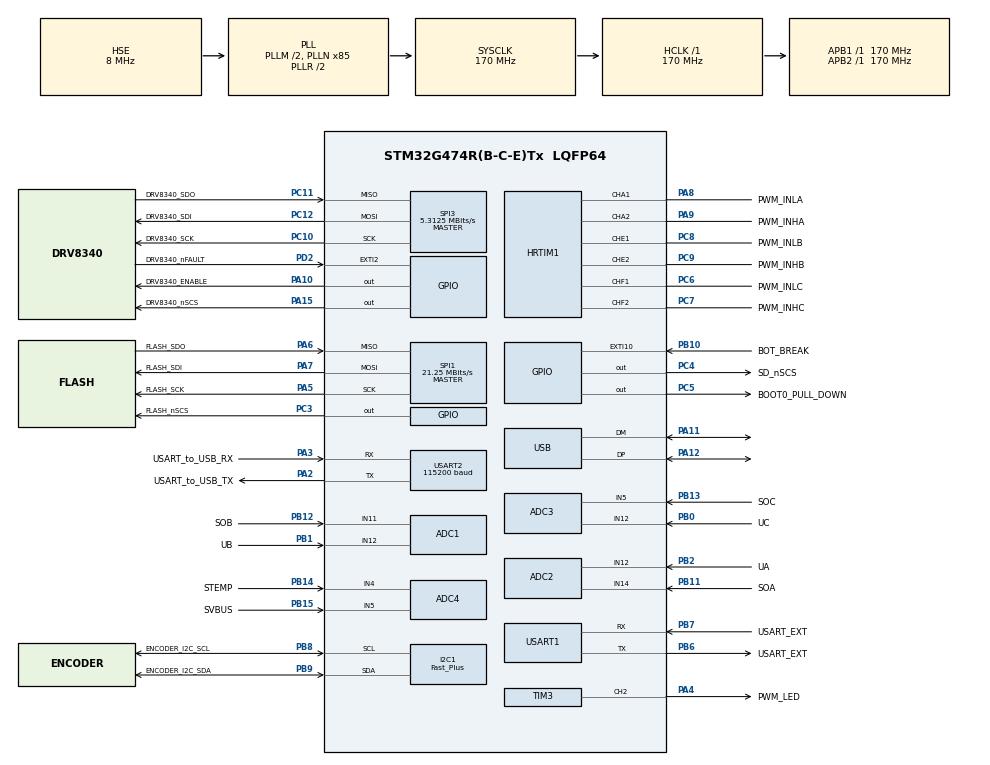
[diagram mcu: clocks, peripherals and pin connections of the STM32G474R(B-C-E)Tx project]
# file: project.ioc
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ADC1.Channel-1\#ChannelRegularConversion=ADC_CHANNEL_11
ADC1.DMAContinuousRequests=ENABLE
ADC1.DiscontinuousConvMode=DISABLE
ADC1.ExternalTrigConv=ADC_EXTERNALTRIG_HRTIM_TRG1
ADC1.ExternalTrigConvEdge=ADC_EXTERNALTRIGCONVEDGE_RISING
ADC1.NbrOfConversion=1
ADC1.NbrOfConversionFlag=1
ADC1.Offset-1\#ChannelRegularConversion=5
ADC1.OffsetNumber-1\#ChannelRegularConversion=ADC_OFFSET_1
ADC1.OffsetSaturation-1\#ChannelRegularConversion=ENABLE
ADC1.Overrun=ADC_OVR_DATA_OVERWRITTEN
ADC1.Rank-1\#ChannelRegularConversion=1
ADC1.SamplingTime-1\#ChannelRegularConversion=ADC_SAMPLETIME_6CYCLES_5
ADC1.master=1
ADC2.Channel-1\#ChannelRegularConversion=ADC_CHANNEL_14
ADC2.DMAContinuousRequests=ENABLE
ADC2.DiscontinuousConvMode=DISABLE
ADC2.ExternalTrigConv=ADC_EXTERNALTRIG_HRTIM_TRG1
ADC2.NbrOfConversion=1
ADC2.NbrOfConversionFlag=1
ADC2.OffsetNumber-1\#ChannelRegularConversion=ADC_OFFSET_NONE
ADC2.Overrun=ADC_OVR_DATA_OVERWRITTEN
ADC2.Rank-1\#ChannelRegularConversion=1
ADC2.SamplingTime-1\#ChannelRegularConversion=ADC_SAMPLETIME_6CYCLES_5
ADC3.Channel-3\#ChannelRegularConversion=ADC_CHANNEL_5
ADC3.DMAContinuousRequests=ENABLE
ADC3.DiscontinuousConvMode=DISABLE
ADC3.ExternalTrigConv=ADC_EXTERNALTRIG_HRTIM_TRG1
ADC3.NbrOfConversion=1
ADC3.NbrOfConversionFlag=1
ADC3.Offset-3\#ChannelRegularConversion=9
ADC3.OffsetNumber-3\#ChannelRegularConversion=ADC_OFFSET_1
ADC3.OffsetSaturation-3\#ChannelRegularConversion=ENABLE
ADC3.OffsetSign-3\#ChannelRegularConversion=ADC_OFFSET_SIGN_POSITIVE
ADC3.Overrun=ADC_OVR_DATA_OVERWRITTEN
ADC3.Rank-3\#ChannelRegularConversion=1
ADC3.SamplingTime-3\#ChannelRegularConversion=ADC_SAMPLETIME_6CYCLES_5
ADC3.master=1
ADC4.Channel-3\#ChannelRegularConversion=ADC_CHANNEL_4
ADC4.Channel-4\#ChannelRegularConversion=ADC_CHANNEL_5
ADC4.DMAContinuousRequests=ENABLE
ADC4.DiscontinuousConvMode=ENABLE
ADC4.ExternalTrigConv=ADC_EXTERNALTRIG_HRTIM_TRG1
ADC4.NbrOfConversion=2
ADC4.NbrOfConversionFlag=1
ADC4.OffsetNumber-3\#ChannelRegularConversion=ADC_OFFSET_NONE
ADC4.OffsetNumber-4\#ChannelRegularConversion=ADC_OFFSET_NONE
ADC4.Overrun=ADC_OVR_DATA_OVERWRITTEN
ADC4.Rank-3\#ChannelRegularConversion=1
ADC4.Rank-4\#ChannelRegularConversion=2
ADC4.SamplingTime-3\#ChannelRegularConversion=ADC_SAMPLETIME_6CYCLES_5
ADC4.SamplingTime-4\#ChannelRegularConversion=ADC_SAMPLETIME_6CYCLES_5
Dma.ADC1.0.Direction=DMA_PERIPH_TO_MEMORY
Dma.ADC1.0.EventEnable=DISABLE
Dma.ADC1.0.Instance=DMA1_Channel1
Dma.ADC1.0.MemDataAlignment=DMA_MDATAALIGN_HALFWORD
Dma.ADC1.0.MemInc=DMA_MINC_ENABLE
Dma.ADC1.0.Mode=DMA_CIRCULAR
Dma.ADC1.0.PeriphDataAlignment=DMA_PDATAALIGN_HALFWORD
Dma.ADC1.0.PeriphInc=DMA_PINC_DISABLE
Dma.ADC1.0.Polarity=HAL_DMAMUX_REQ_GEN_RISING
Dma.ADC1.0.Priority=DMA_PRIORITY_VERY_HIGH
Dma.ADC1.0.RequestNumber=1
Dma.ADC1.0.SignalID=NONE
Dma.ADC1.0.SyncEnable=DISABLE
Dma.ADC1.0.SyncPolarity=HAL_DMAMUX_SYNC_NO_EVENT
Dma.ADC1.0.SyncRequestNumber=1
Dma.ADC1.0.SyncSignalID=NONE
Dma.ADC2.3.Direction=DMA_PERIPH_TO_MEMORY
Dma.ADC2.3.EventEnable=DISABLE
Dma.ADC2.3.Instance=DMA1_Channel2
Dma.ADC2.3.MemDataAlignment=DMA_MDATAALIGN_HALFWORD
Dma.ADC2.3.MemInc=DMA_MINC_ENABLE
Dma.ADC2.3.Mode=DMA_CIRCULAR
Dma.ADC2.3.PeriphDataAlignment=DMA_PDATAALIGN_HALFWORD
Dma.ADC2.3.PeriphInc=DMA_PINC_DISABLE
Dma.ADC2.3.Polarity=HAL_DMAMUX_REQ_GEN_RISING
Dma.ADC2.3.Priority=DMA_PRIORITY_VERY_HIGH
Dma.ADC2.3.RequestNumber=1
Dma.ADC2.3.SignalID=NONE
Dma.ADC2.3.SyncEnable=DISABLE
Dma.ADC2.3.SyncPolarity=HAL_DMAMUX_SYNC_NO_EVENT
Dma.ADC2.3.SyncRequestNumber=1
Dma.ADC2.3.SyncSignalID=NONE
Dma.ADC3.4.Direction=DMA_PERIPH_TO_MEMORY
Dma.ADC3.4.EventEnable=DISABLE
Dma.ADC3.4.Instance=DMA1_Channel3
Dma.ADC3.4.MemDataAlignment=DMA_MDATAALIGN_HALFWORD
Dma.ADC3.4.MemInc=DMA_MINC_ENABLE
Dma.ADC3.4.Mode=DMA_CIRCULAR
Dma.ADC3.4.PeriphDataAlignment=DMA_PDATAALIGN_HALFWORD
Dma.ADC3.4.PeriphInc=DMA_PINC_DISABLE
Dma.ADC3.4.Polarity=HAL_DMAMUX_REQ_GEN_RISING
Dma.ADC3.4.Priority=DMA_PRIORITY_VERY_HIGH
Dma.ADC3.4.RequestNumber=1
Dma.ADC3.4.SignalID=NONE
Dma.ADC3.4.SyncEnable=DISABLE
Dma.ADC3.4.SyncPolarity=HAL_DMAMUX_SYNC_NO_EVENT
Dma.ADC3.4.SyncRequestNumber=1
Dma.ADC3.4.SyncSignalID=NONE
Dma.ADC4.5.Direction=DMA_PERIPH_TO_MEMORY
Dma.ADC4.5.EventEnable=DISABLE
Dma.ADC4.5.Instance=DMA2_Channel2
Dma.ADC4.5.MemDataAlignment=DMA_MDATAALIGN_HALFWORD
Dma.ADC4.5.MemInc=DMA_MINC_ENABLE
Dma.ADC4.5.Mode=DMA_CIRCULAR
Dma.ADC4.5.PeriphDataAlignment=DMA_PDATAALIGN_HALFWORD
Dma.ADC4.5.PeriphInc=DMA_PINC_DISABLE
Dma.ADC4.5.Polarity=HAL_DMAMUX_REQ_GEN_RISING
Dma.ADC4.5.Priority=DMA_PRIORITY_LOW
Dma.ADC4.5.RequestNumber=1
Dma.ADC4.5.SignalID=NONE
Dma.ADC4.5.SyncEnable=DISABLE
Dma.ADC4.5.SyncPolarity=HAL_DMAMUX_SYNC_NO_EVENT
Dma.ADC4.5.SyncRequestNumber=1
Dma.ADC4.5.SyncSignalID=NONE
Dma.I2C1_RX.2.Direction=DMA_PERIPH_TO_MEMORY
Dma.I2C1_RX.2.EventEnable=DISABLE
Dma.I2C1_RX.2.Instance=DMA2_Channel1
Dma.I2C1_RX.2.MemDataAlignment=DMA_MDATAALIGN_BYTE
Dma.I2C1_RX.2.MemInc=DMA_MINC_ENABLE
Dma.I2C1_RX.2.Mode=DMA_NORMAL
Dma.I2C1_RX.2.PeriphDataAlignment=DMA_PDATAALIGN_BYTE
Dma.I2C1_RX.2.PeriphInc=DMA_PINC_DISABLE
Dma.I2C1_RX.2.Polarity=HAL_DMAMUX_REQ_GEN_RISING
Dma.I2C1_RX.2.Priority=DMA_PRIORITY_HIGH
Dma.I2C1_RX.2.RequestNumber=1
Dma.I2C1_RX.2.SignalID=NONE
Dma.I2C1_RX.2.SyncEnable=DISABLE
Dma.I2C1_RX.2.SyncPolarity=HAL_DMAMUX_SYNC_NO_EVENT
Dma.I2C1_RX.2.SyncRequestNumber=1
Dma.I2C1_RX.2.SyncSignalID=NONE
Dma.Request0=ADC1
Dma.Request1=TIM3_CH2
Dma.Request2=I2C1_RX
Dma.Request3=ADC2
Dma.Request4=ADC3
Dma.Request5=ADC4
Dma.TIM3_CH2.1.Direction=DMA_MEMORY_TO_PERIPH
Dma.TIM3_CH2.1.EventEnable=DISABLE
Dma.TIM3_CH2.1.Instance=DMA2_Channel3
Dma.TIM3_CH2.1.MemDataAlignment=DMA_MDATAALIGN_BYTE
Dma.TIM3_CH2.1.MemInc=DMA_MINC_ENABLE
Dma.TIM3_CH2.1.Mode=DMA_NORMAL
Dma.TIM3_CH2.1.PeriphDataAlignment=DMA_PDATAALIGN_HALFWORD
Dma.TIM3_CH2.1.PeriphInc=DMA_PINC_DISABLE
Dma.TIM3_CH2.1.Polarity=HAL_DMAMUX_REQ_GEN_RISING
Dma.TIM3_CH2.1.Priority=DMA_PRIORITY_LOW
Dma.TIM3_CH2.1.RequestNumber=1
Dma.TIM3_CH2.1.SignalID=NONE
Dma.TIM3_CH2.1.SyncEnable=DISABLE
Dma.TIM3_CH2.1.SyncPolarity=HAL_DMAMUX_SYNC_NO_EVENT
Dma.TIM3_CH2.1.SyncRequestNumber=1
Dma.TIM3_CH2.1.SyncSignalID=NONE
HRTIM1.ADCTrigger1_Source1=HRTIM_ADCTRIGGEREVENT13_MASTER_CMP4
HRTIM1.ADCTrigger_Id1=HRTIM_ADCTRIGGER_1
HRTIM1.ADCTrigger_Id2=__NULL
HRTIM1.ADCTrigger_Id3=__NULL
HRTIM1.ADCTrigger_Id4=__NULL
HRTIM1.CompareUnit1-MasterTimer=HRTIM_COMPAREUNIT_1
HRTIM1.CompareUnit1-Output_TA1TA2=__NULL
HRTIM1.CompareUnit1-Output_TE1TE2=__NULL
HRTIM1.CompareUnit1-Output_TF1TF2=__NULL
HRTIM1.CompareUnit2-MasterTimer=HRTIM_COMPAREUNIT_2
HRTIM1.CompareUnit2-Output_TA1TA2=__NULL
HRTIM1.CompareUnit3-MasterTimer=HRTIM_COMPAREUNIT_3
HRTIM1.CompareUnit3-Output_TA1TA2=__NULL
HRTIM1.CompareUnit4-MasterTimer=HRTIM_COMPAREUNIT_4
HRTIM1.CompareValue1-MasterTimer=36
HRTIM1.CompareValue2-MasterTimer=36
HRTIM1.CompareValue3-MasterTimer=36
HRTIM1.CompareValue4-MasterTimer=36
HRTIM1.Configuration_TA=Waveform
HRTIM1.Configuration_TE=Waveform
HRTIM1.Configuration_TF=Waveform
HRTIM1.DeadTimeInsertion-Output_TA1TA2=HRTIM_TIMDEADTIMEINSERTION_ENABLED
HRTIM1.DeadTimeInsertion-Output_TE1TE2=HRTIM_TIMDEADTIMEINSERTION_ENABLED
HRTIM1.DeadTimeInsertion-Output_TF1TF2=HRTIM_TIMDEADTIMEINSERTION_ENABLED
HRTIM1.EnableCalibration=DLLSimpleCalibration
HRTIM1.InterruptRequests1_Master=HRTIM_MASTER_IT_MREP
HRTIM1.NumberADCTriggerSource1=1
HRTIM1.NumberInterruptRequests-Output_TA1TA2=0
HRTIM1.NumberInterruptRequests_Master-MasterTimer=1
HRTIM1.NumberResetSource1-Output_TA1TA2=1
HRTIM1.NumberResetSource1-Output_TE1TE2=1
HRTIM1.NumberResetSource1-Output_TF1TF2=1
HRTIM1.NumberResetTrigger-Output_TA1TA2=0
HRTIM1.NumberResetTrigger-Output_TE1TE2=0
HRTIM1.NumberResetTrigger-Output_TF1TF2=0
HRTIM1.NumberSetSource1-Output_TA1TA2=1
HRTIM1.NumberSetSource1-Output_TE1TE2=1
HRTIM1.NumberSetSource1-Output_TF1TF2=1
HRTIM1.NumberUpdateTrigger-Output_TA1TA2=0
HRTIM1.NumberUpdateTrigger-Output_TE1TE2=0
HRTIM1.NumberUpdateTrigger-Output_TF1TF2=0
HRTIM1.ORingUpdateSource_ADCTrigger1=HRTIM_ADCTRIGGERUPDATE_MASTER
HRTIM1.Periode_MASTER=32000
HRTIM1.Periode_TA=32000
HRTIM1.Periode_TE=32000
HRTIM1.Periode_TF=32000
HRTIM1.PreloadEnable-MasterTimer=HRTIM_PRELOAD_ENABLED
HRTIM1.PreloadEnable-Output_TA1TA2=HRTIM_PRELOAD_ENABLED
HRTIM1.PreloadEnable-Output_TE1TE2=HRTIM_PRELOAD_ENABLED
HRTIM1.PreloadEnable-Output_TF1TF2=HRTIM_PRELOAD_ENABLED
HRTIM1.PrescalerRatio_MASTER=HRTIM_PRESCALERRATIO_MUL8
HRTIM1.PrescalerRatio_TA=HRTIM_PRESCALERRATIO_MUL8
HRTIM1.PrescalerRatio_TE=HRTIM_PRESCALERRATIO_MUL8
HRTIM1.PrescalerRatio_TF=HRTIM_PRESCALERRATIO_MUL8
HRTIM1.PushPull-Output_TA1TA2=HRTIM_TIMPUSHPULLMODE_DISABLED
HRTIM1.PushPull-Output_TE1TE2=HRTIM_TIMPUSHPULLMODE_DISABLED
HRTIM1.PushPull-Output_TF1TF2=HRTIM_TIMPUSHPULLMODE_DISABLED
HRTIM1.RepetitionCounter-MasterTimer=1-1
HRTIM1.RepetitionUpdate-MasterTimer=HRTIM_UPDATEONREPETITION_ENABLED
HRTIM1.RepetitionUpdate-Output_TA1TA2=HRTIM_UPDATEONREPETITION_ENABLED
HRTIM1.RepetitionUpdate-Output_TE1TE2=HRTIM_UPDATEONREPETITION_ENABLED
HRTIM1.RepetitionUpdate-Output_TF1TF2=HRTIM_UPDATEONREPETITION_ENABLED
HRTIM1.ResetOutput1_Source1-Output_TA1TA2=HRTIM_OUTPUTRESET_MASTERPER
HRTIM1.ResetOutput1_Source1-Output_TE1TE2=HRTIM_OUTPUTRESET_MASTERPER
HRTIM1.ResetOutput1_Source1-Output_TF1TF2=HRTIM_OUTPUTRESET_MASTERPER
HRTIM1.ResetUpdate-Output_TA1TA2=HRTIM_TIMUPDATEONRESET_DISABLED
HRTIM1.ResetUpdate-Output_TE1TE2=HRTIM_TIMUPDATEONRESET_DISABLED
HRTIM1.ResetUpdate-Output_TF1TF2=HRTIM_TIMUPDATEONRESET_DISABLED
HRTIM1.SetOutput1_Source1-Output_TA1TA2=HRTIM_OUTPUTSET_MASTERCMP1
HRTIM1.SetOutput1_Source1-Output_TE1TE2=HRTIM_OUTPUTSET_MASTERCMP2
HRTIM1.SetOutput1_Source1-Output_TF1TF2=HRTIM_OUTPUTSET_MASTERCMP3
HRTIM1.StartOnSync-MasterTimer=HRTIM_SYNCSTART_DISABLED
HRTIM1.SyncOptions=HRTIM_SYNCOPTION_MASTER
HRTIM1.SyncOutputPolarity=HRTIM_SYNCOUTPUTPOLARITY_POSITIVE
HRTIM1.Timeout=100
HRTIM1.UpDownMode-Output_TA1TA2=HRTIM_TIMERUPDOWNMODE_UP
HRTIM1.UpDownMode-Output_TE1TE2=HRTIM_TIMERUPDOWNMODE_UP
HRTIM1.UpDownMode-Output_TF1TF2=HRTIM_TIMERUPDOWNMODE_UP
I2C1.I2C_Speed_Mode=I2C_Fast_Plus
I2C1.Timing=0x4052060F
Mcu.Family=STM32G4
Mcu.Name=STM32G474R(B-C-E)Tx
Mcu.Package=LQFP64
NVIC.DMA2_Channel1_IRQn=true\:7\:0\:true\:false\:true\:true\:true\:true
NVIC.DMA2_Channel3_IRQn=true\:3\:0\:true\:false\:true\:true\:true\:true
NVIC.EXTI15_10_IRQn=true\:0\:1\:false\:false\:true\:true\:true\:true
NVIC.EXTI2_IRQn=true\:0\:0\:false\:false\:true\:true\:true\:true
NVIC.HRTIM1_Master_IRQn=true\:0\:0\:false\:false\:true\:true\:true\:true
NVIC.I2C1_ER_IRQn=true\:7\:0\:true\:false\:true\:true\:true\:true
NVIC.I2C1_EV_IRQn=true\:4\:0\:true\:false\:true\:true\:true\:true
NVIC.PriorityGroup=NVIC_PRIORITYGROUP_3
NVIC.USB_HP_IRQn=true\:3\:0\:true\:false\:true\:true\:true\:true
NVIC.USB_LP_IRQn=true\:3\:0\:true\:false\:true\:false\:true\:true
PA10.GPIO_Label=DRV8340_ENABLE
PA10.GPIO_Speed=GPIO_SPEED_FREQ_VERY_HIGH
PA10.Signal=GPIO_Output
PA11.Mode=Device
PA11.Signal=USB_DM
PA12.Mode=Device
PA12.Signal=USB_DP
PA13.Mode=Serial_Wire
PA13.Signal=SYS_JTMS-SWDIO
PA14.Mode=Serial_Wire
PA14.Signal=SYS_JTCK-SWCLK
PA15.GPIO_Label=DRV8340_nSCS
PA15.GPIO_Speed=GPIO_SPEED_FREQ_VERY_HIGH
PA15.PinState=GPIO_PIN_SET
PA15.Signal=GPIO_Output
PA2.GPIO_Label=USART_to_USB_TX
PA2.Mode=Asynchronous
PA2.Signal=USART2_TX
PA3.GPIO_Label=USART_to_USB_RX
PA3.Mode=Asynchronous
PA3.Signal=USART2_RX
PA4.GPIO_Label=PWM_LED
PA4.GPIO_Speed=GPIO_SPEED_FREQ_VERY_HIGH
PA4.Signal=S_TIM3_CH2
PA5.GPIO_Label=FLASH_SCK
PA5.Mode=Full_Duplex_Master
PA5.Signal=SPI1_SCK
PA6.GPIO_Label=FLASH_SDO
PA6.Mode=Full_Duplex_Master
PA6.Signal=SPI1_MISO
PA7.GPIO_Label=FLASH_SDI
PA7.Mode=Full_Duplex_Master
PA7.Signal=SPI1_MOSI
PA8.GPIO_Label=PWM_INLA
PA8.Mode=Output_TA1TA2
PA8.Signal=HRTIM1_CHA1
PA9.GPIO_Label=PWM_INHA
PA9.Mode=Output_TA1TA2
PA9.Signal=HRTIM1_CHA2
PB0.GPIO_Label=UC
PB0.Mode=IN12-Single-Ended
PB0.Signal=ADC3_IN12
PB1.GPIO_Label=UB
PB1.Mode=IN12-Single-Ended
PB1.Signal=ADC1_IN12
PB10.GPIO_Label=BOT_BREAK
PB10.GPIO_ModeDefaultEXTI=GPIO_MODE_IT_FALLING
PB10.Signal=GPXTI10
PB11.GPIO_Label=SOA
PB11.Mode=IN14-Single-Ended
PB11.Signal=ADC2_IN14
PB12.GPIO_Label=SOB
PB12.Mode=IN11-Single-Ended
PB12.Signal=ADC1_IN11
PB13.GPIO_Label=SOC
PB13.Mode=IN5-Single-Ended
PB13.Signal=ADC3_IN5
PB14.GPIO_Label=STEMP
PB14.Mode=IN4-Single-Ended
PB14.Signal=ADC4_IN4
PB15.GPIO_Label=SVBUS
PB15.Mode=IN5-Single-Ended
PB15.Signal=ADC4_IN5
PB2.GPIO_Label=UA
PB2.Mode=IN12-Single-Ended
PB2.Signal=ADC2_IN12
PB6.GPIO_Label=USART_EXT
PB6.Mode=Asynchronous
PB6.Signal=USART1_TX
PB7.GPIO_Label=USART_EXT
PB7.Mode=Asynchronous
PB7.Signal=USART1_RX
PB8-BOOT0.GPIO_FM8=SYSCFG_FASTMODEPLUS_PB8
PB8-BOOT0.GPIO_Label=ENCODER_I2C_SCL
PB8-BOOT0.GPIO_Speed=GPIO_SPEED_FREQ_VERY_HIGH
PB8-BOOT0.Mode=I2C
PB8-BOOT0.Signal=I2C1_SCL
PB9.GPIO_FM9=SYSCFG_FASTMODEPLUS_PB9
PB9.GPIO_Label=ENCODER_I2C_SDA
PB9.GPIO_Speed=GPIO_SPEED_FREQ_VERY_HIGH
PB9.Mode=I2C
PB9.Signal=I2C1_SDA
PC10.GPIO_Label=DRV8340_SCK
PC10.Mode=Full_Duplex_Master
PC10.Signal=SPI3_SCK
PC11.GPIO_Label=DRV8340_SDO
PC11.Mode=Full_Duplex_Master
PC11.Signal=SPI3_MISO
PC12.GPIO_Label=DRV8340_SDI
PC12.Mode=Full_Duplex_Master
PC12.Signal=SPI3_MOSI
PC3.GPIO_Label=FLASH_nSCS
PC3.GPIO_Speed=GPIO_SPEED_FREQ_VERY_HIGH
PC3.PinState=GPIO_PIN_SET
PC3.Signal=GPIO_Output
PC4.GPIO_Label=SD_nSCS
PC4.GPIO_Speed=GPIO_SPEED_FREQ_VERY_HIGH
PC4.PinState=GPIO_PIN_SET
PC4.Signal=GPIO_Output
PC5.GPIO_Label=BOOT0_PULL_DOWN
PC5.GPIO_Speed=GPIO_SPEED_FREQ_VERY_HIGH
PC5.PinState=GPIO_PIN_SET
PC5.Signal=GPIO_Output
PC6.GPIO_Label=PWM_INLC
PC6.Mode=Output_TF1TF2
PC6.Signal=HRTIM1_CHF1
PC7.GPIO_Label=PWM_INHC
PC7.Mode=Output_TF1TF2
PC7.Signal=HRTIM1_CHF2
PC8.GPIO_Label=PWM_INLB
PC8.Mode=Output_TE1TE2
PC8.Signal=HRTIM1_CHE1
PC9.GPIO_Label=PWM_INHB
PC9.Mode=Output_TE1TE2
PC9.Signal=HRTIM1_CHE2
PD2.GPIO_Label=DRV8340_nFAULT
PD2.GPIO_ModeDefaultEXTI=GPIO_MODE_IT_FALLING
PD2.Signal=GPXTI2
PF0-OSC_IN.Mode=HSE-External-Oscillator
PF0-OSC_IN.Signal=RCC_OSC_IN
PF1-OSC_OUT.Mode=HSE-External-Oscillator
PF1-OSC_OUT.Signal=RCC_OSC_OUT
ProjectManager.HeapSize=0x200
ProjectManager.StackSize=0x800
ProjectManager.TargetToolchain=CMake
RCC.ADC12Freq_Value=170000000
RCC.ADC345Freq_Value=170000000
RCC.AHBFreq_Value=170000000
RCC.APB1Freq_Value=170000000
RCC.APB1TimFreq_Value=170000000
RCC.APB2Freq_Value=170000000
RCC.APB2TimFreq_Value=170000000
RCC.CK48CLockSelection=RCC_USBCLKSOURCE_HSI48
RCC.CortexFreq_Value=170000000
RCC.EXTERNAL_CLOCK_VALUE=12288000
RCC.HCLKFreq_Value=170000000
RCC.HSE_VALUE=8000000
RCC.HSI48_VALUE=48000000
RCC.HSI_VALUE=16000000
RCC.LSE_VALUE=32768
RCC.PLLM=RCC_PLLM_DIV2
RCC.PLLN=85
RCC.PLLSourceVirtual=RCC_PLLSOURCE_HSE
RCC.SYSCLKFreq_VALUE=170000000
RCC.SYSCLKSource=RCC_SYSCLKSOURCE_PLLCLK
RCC.USBFreq_Value=48000000
RCC.VCOOutputFreq_Value=340000000
SH.S_TIM3_CH2.0=TIM3_CH2,PWM Generation2 CH2
SPI1.BaudRatePrescaler=SPI_BAUDRATEPRESCALER_8
SPI1.CLKPhase=SPI_PHASE_1EDGE
SPI1.CalculateBaudRate=21.25 MBits/s
SPI1.DataSize=SPI_DATASIZE_8BIT
SPI1.Direction=SPI_DIRECTION_2LINES
SPI1.Mode=SPI_MODE_MASTER
SPI1.VirtualType=VM_MASTER
SPI3.BaudRatePrescaler=SPI_BAUDRATEPRESCALER_32
SPI3.CLKPhase=SPI_PHASE_2EDGE
SPI3.CalculateBaudRate=5.3125 MBits/s
SPI3.DataSize=SPI_DATASIZE_16BIT
SPI3.Direction=SPI_DIRECTION_2LINES
SPI3.Mode=SPI_MODE_MASTER
SPI3.VirtualType=VM_MASTER
TIM2.AutoReloadPreload=TIM_AUTORELOAD_PRELOAD_ENABLE
TIM2.Prescaler=17-1
TIM3.AutoReloadPreload=TIM_AUTORELOAD_PRELOAD_ENABLE
TIM3.Channel-PWM\ Generation2\ CH2=TIM_CHANNEL_2
TIM3.OCPolarity_2=TIM_OCPOLARITY_HIGH
TIM3.PeriodNoDither=12-1
TIM3.Prescaler=17-1
USART1.VirtualMode-Asynchronous=VM_ASYNC
USART2.BaudRate=115200
USART2.OverSampling=UART_OVERSAMPLING_16
USART2.VirtualMode-Asynchronous=VM_ASYNC
USB_DEVICE.APP_RX_DATA_SIZE=256
USB_DEVICE.CLASS_NAME_FS=CDC
USB_DEVICE.USBD_LPM_ENABLED=0
USB_DEVICE.VirtualMode=Cdc
USB_DEVICE.VirtualModeFS=Cdc_FS
VP_CORDIC_VS_CORDIC.Mode=CORDIC_Activate
VP_HRTIM1_VS_hrtimMasterTimerNoOutput.Mode=MasterTimer
VP_SYS_VS_DBSignals.Mode=DisableDeadBatterySignals
VP_SYS_V_VREFBUF.Mode=ExternalMode
VP_TIM2_VS_ClockSourceINT.Mode=Internal
VP_TIM3_VS_ClockSourceINT.Mode=Internal
VP_USB_DEVICE_VS_USB_DEVICE_CDC_FS.Mode=CDC_FS
board=custom

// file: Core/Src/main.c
/* USER CODE BEGIN Header */
/**
  ******************************************************************************
  * @file           : main.c
  * @brief          : Main program body
  ******************************************************************************
  * @attention
  *
  * Copyright (c) 2026 STMicroelectronics.
  * All rights reserved.
  *
  * This software is licensed under terms that can be found in the LICENSE file
  * in the root directory of this software component.
  * If no LICENSE file comes with this software, it is provided AS-IS.
  *
  ******************************************************************************
  */
/* USER CODE END Header */
#include "main.h"
#include "adc.h"
#include "cordic.h"
#include "dma.h"
#include "hrtim.h"
#include "i2c.h"
#include "spi.h"
#include "tim.h"
#include "usart.h"
#include "usb_device.h"
#include "gpio.h"

/* USER CODE BEGIN Includes */
#include "rgb.h"
#include <stdint.h>
#include <stdio.h>
#include "drv8340s.h"
#include "mc_ctrl.h"
#include "jf.h"
#include "usb.h"
#include "usbd_cdc.h"

/* USER CODE END Includes */

void SystemClock_Config(void);

int main(void)
{

  /* MCU Configuration--------------------------------------------------------*/

  /* Reset of all peripherals, Initializes the Flash interface and the Systick. */
  HAL_Init();

  /* Configure the system clock */
  SystemClock_Config();

  /* Initialize all configured peripherals */
  MX_GPIO_Init();
  MX_DMA_Init();
  MX_ADC1_Init();
  MX_HRTIM1_Init();
  MX_ADC2_Init();
  MX_ADC3_Init();
  MX_ADC4_Init();
  MX_SPI1_Init();
  MX_SPI3_Init();
  MX_USART2_UART_Init();
  MX_I2C1_Init();
  MX_TIM3_Init();
  MX_USART1_UART_Init();
  MX_USB_Device_Init();
  MX_CORDIC_Init();
  MX_TIM2_Init();
  /* USER CODE BEGIN 2 */
  RGB_Init();
  MOTOR_Init();

  /* USER CODE END 2 */

  /* Infinite loop */
  /* USER CODE BEGIN WHILE */
  while (1)
  {
    MOTOR_Start_Task();
    JF_Task();
    FOC_Usb_Task();

  }
    /* USER CODE END WHILE */

}

void SystemClock_Config(void)
{
  RCC_OscInitTypeDef RCC_OscInitStruct = {0};
  RCC_ClkInitTypeDef RCC_ClkInitStruct = {0};

  /** Configure the main internal regulator output voltage
  */
  HAL_PWREx_ControlVoltageScaling(PWR_REGULATOR_VOLTAGE_SCALE1_BOOST);

  /** Initializes the RCC Oscillators according to the specified parameters
  * in the RCC_OscInitTypeDef structure.
  */
  RCC_OscInitStruct.OscillatorType = RCC_OSCILLATORTYPE_HSI48|RCC_OSCILLATORTYPE_HSE;
  RCC_OscInitStruct.HSEState = RCC_HSE_ON;
  RCC_OscInitStruct.HSI48State = RCC_HSI48_ON;
  RCC_OscInitStruct.PLL.PLLState = RCC_PLL_ON;
  RCC_OscInitStruct.PLL.PLLSource = RCC_PLLSOURCE_HSE;
  RCC_OscInitStruct.PLL.PLLM = RCC_PLLM_DIV2;
  RCC_OscInitStruct.PLL.PLLN = 85;
  RCC_OscInitStruct.PLL.PLLP = RCC_PLLP_DIV2;
  RCC_OscInitStruct.PLL.PLLQ = RCC_PLLQ_DIV2;
  RCC_OscInitStruct.PLL.PLLR = RCC_PLLR_DIV2;
  if (HAL_RCC_OscConfig(&RCC_OscInitStruct) != HAL_OK)
  {
    Error_Handler();
  }

  /** Initializes the CPU, AHB and APB buses clocks
  */
  RCC_ClkInitStruct.ClockType = RCC_CLOCKTYPE_HCLK|RCC_CLOCKTYPE_SYSCLK
                              |RCC_CLOCKTYPE_PCLK1|RCC_CLOCKTYPE_PCLK2;
  RCC_ClkInitStruct.SYSCLKSource = RCC_SYSCLKSOURCE_PLLCLK;
  RCC_ClkInitStruct.AHBCLKDivider = RCC_SYSCLK_DIV1;
  RCC_ClkInitStruct.APB1CLKDivider = RCC_HCLK_DIV1;
  RCC_ClkInitStruct.APB2CLKDivider = RCC_HCLK_DIV1;

  if (HAL_RCC_ClockConfig(&RCC_ClkInitStruct, FLASH_LATENCY_4) != HAL_OK)
  {
    Error_Handler();
  }
}

/* USER CODE BEGIN 4 */
// int __io_putchar(int ch)
// {
//     HAL_UART_Transmit(&huart2, (uint8_t *)&ch, 1, 10);
//     return ch;
// }
/* USER CODE END 4 */

void Error_Handler(void)
{
  __disable_irq();
  while (1)
  {
  }
}
